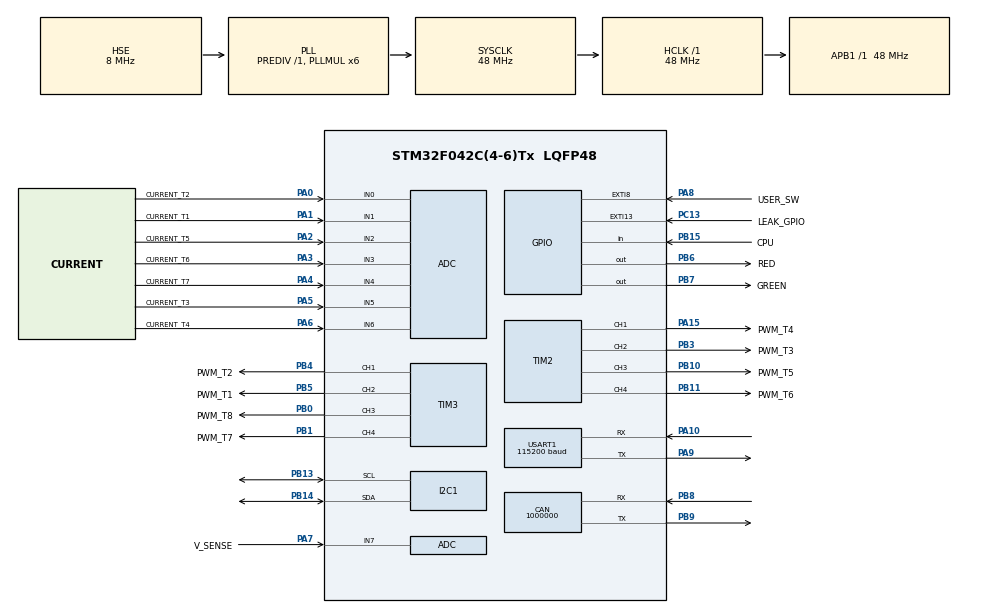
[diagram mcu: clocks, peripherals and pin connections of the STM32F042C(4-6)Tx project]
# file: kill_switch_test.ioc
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CAN.CalculateBaudRate=1000000
CAN.CalculateTimeQuantum=333.3333333333333
Mcu.Family=STM32F0
Mcu.Name=STM32F042C(4-6)Tx
Mcu.Package=LQFP48
PA0.GPIO_Label=CURRENT_T2
PA0.Mode=IN0
PA0.Signal=ADC_IN0
PA1.GPIO_Label=CURRENT_T1
PA1.Mode=IN1
PA1.Signal=ADC_IN1
PA10.Mode=Asynchronous
PA10.Signal=USART1_RX
PA15.GPIO_Label=PWM_T4
PA15.Signal=S_TIM2_CH1_ETR
PA2.GPIO_Label=CURRENT_T5
PA2.Mode=IN2
PA2.Signal=ADC_IN2
PA3.GPIO_Label=CURRENT_T6
PA3.Mode=IN3
PA3.Signal=ADC_IN3
PA4.GPIO_Label=CURRENT_T7
PA4.Mode=IN4
PA4.Signal=ADC_IN4
PA5.GPIO_Label=CURRENT_T3
PA5.Mode=IN5
PA5.Signal=ADC_IN5
PA6.GPIO_Label=CURRENT_T4
PA6.Mode=IN6
PA6.Signal=ADC_IN6
PA7.GPIO_Label=V_SENSE
PA7.Mode=IN7
PA7.Signal=ADC_IN7
PA8.GPIO_Label=USER_SW
PA8.GPIO_ModeDefaultEXTI=GPIO_MODE_EVT_RISING_FALLING
PA8.GPIO_PuPd=GPIO_NOPULL
PA8.Signal=GPXTI8
PA9.Mode=Asynchronous
PA9.Signal=USART1_TX
PB0.GPIO_Label=PWM_T8
PB0.Signal=S_TIM3_CH3
PB1.GPIO_Label=PWM_T7
PB1.Signal=S_TIM3_CH4
PB10.GPIO_Label=PWM_T5
PB10.Signal=S_TIM2_CH3
PB11.GPIO_Label=PWM_T6
PB11.Signal=S_TIM2_CH4
PB13.Mode=I2C
PB13.Signal=I2C1_SCL
PB14.Mode=I2C
PB14.Signal=I2C1_SDA
PB15.GPIO_Label=CPU
PB15.Signal=GPIO_Input
PB3.GPIO_Label=PWM_T3
PB3.Signal=S_TIM2_CH2
PB4.GPIO_Label=PWM_T2
PB4.Signal=S_TIM3_CH1
PB5.GPIO_Label=PWM_T1
PB5.Signal=S_TIM3_CH2
PB6.GPIO_Label=RED
PB6.PinState=GPIO_PIN_SET
PB6.Signal=GPIO_Output
PB7.GPIO_Label=GREEN
PB7.Signal=GPIO_Output
PB8.Mode=CAN_Activate
PB8.Signal=CAN_RX
PB9.Mode=CAN_Activate
PB9.Signal=CAN_TX
PC13.GPIO_Label=LEAK_GPIO
PC13.GPIO_ModeDefaultEXTI=GPIO_MODE_EVT_RISING_FALLING
PC13.Signal=GPXTI13
PF0-OSC_IN.Mode=HSE-External-Oscillator
PF0-OSC_IN.Signal=RCC_OSC_IN
PF1-OSC_OUT.Mode=HSE-External-Oscillator
PF1-OSC_OUT.Signal=RCC_OSC_OUT
ProjectManager.HeapSize=0x200
ProjectManager.StackSize=0x400
ProjectManager.TargetToolchain=STM32CubeIDE
RCC.AHBFreq_Value=48000000
RCC.APB1Freq_Value=48000000
RCC.APB1TimFreq_Value=48000000
RCC.HCLKFreq_Value=48000000
RCC.PLLMUL=RCC_PLL_MUL6
RCC.PLLSourceVirtual=RCC_PLLSOURCE_HSE
RCC.SYSCLKFreq_VALUE=48000000
RCC.SYSCLKSource=RCC_SYSCLKSOURCE_PLLCLK
SH.S_TIM2_CH1_ETR.0=TIM2_CH1,PWM Generation1 CH1
SH.S_TIM2_CH2.0=TIM2_CH2,PWM Generation2 CH2
SH.S_TIM2_CH3.0=TIM2_CH3,PWM Generation3 CH3
SH.S_TIM2_CH4.0=TIM2_CH4,PWM Generation4 CH4
SH.S_TIM3_CH1.0=TIM3_CH1,PWM Generation1 CH1
SH.S_TIM3_CH2.0=TIM3_CH2,PWM Generation2 CH2
SH.S_TIM3_CH3.0=TIM3_CH3,PWM Generation3 CH3
SH.S_TIM3_CH4.0=TIM3_CH4,PWM Generation4 CH4
TIM2.Channel-PWM\ Generation1\ CH1=TIM_CHANNEL_1
TIM2.Channel-PWM\ Generation2\ CH2=TIM_CHANNEL_2
TIM2.Channel-PWM\ Generation3\ CH3=TIM_CHANNEL_3
TIM2.Channel-PWM\ Generation4\ CH4=TIM_CHANNEL_4
TIM3.Channel-PWM\ Generation1\ CH1=TIM_CHANNEL_1
TIM3.Channel-PWM\ Generation2\ CH2=TIM_CHANNEL_2
TIM3.Channel-PWM\ Generation3\ CH3=TIM_CHANNEL_3
TIM3.Channel-PWM\ Generation4\ CH4=TIM_CHANNEL_4
USART1.BaudRate=115200
USART1.VirtualMode-Asynchronous=VM_ASYNC
board=custom

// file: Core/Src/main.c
/* USER CODE BEGIN Header */
/**
  ******************************************************************************
  * @file           : main.c
  * @brief          : Main program body
  ******************************************************************************
  * @attention
  *
  * Copyright (c) 2023 STMicroelectronics.
  * All rights reserved.
  *
  * This software is licensed under terms that can be found in the LICENSE file
  * in the root directory of this software component.
  * If no LICENSE file comes with this software, it is provided AS-IS.
  *
  ******************************************************************************
  */
/* USER CODE END Header */
#include "main.h"

/* USER CODE BEGIN Includes */
#include "printf.h"
#include "string.h"
/* USER CODE END Includes */

ADC_HandleTypeDef hadc;

CAN_HandleTypeDef hcan;

I2C_HandleTypeDef hi2c1;

TIM_HandleTypeDef htim2;
TIM_HandleTypeDef htim3;

UART_HandleTypeDef huart1;

/* USER CODE BEGIN PV */
String KILL_LEAK = "LEAK";
/* USER CODE END PV */

void SystemClock_Config(void);
static void MX_GPIO_Init(void);
static void MX_USART1_UART_Init(void);
static void MX_ADC_Init(void);
static void MX_CAN_Init(void);
static void MX_TIM2_Init(void);
static void MX_TIM3_Init(void);
static void MX_I2C1_Init(void);

int main(void)
{

  /* MCU Configuration--------------------------------------------------------*/

  /* Reset of all peripherals, Initializes the Flash interface and the Systick. */
  HAL_Init();

  /* Configure the system clock */
  SystemClock_Config();

  /* Initialize all configured peripherals */
  MX_GPIO_Init();
  MX_USART1_UART_Init();
  MX_ADC_Init();
  MX_CAN_Init();
  MX_TIM2_Init();
  MX_TIM3_Init();
  MX_I2C1_Init();

  /* Infinite loop */
  /* USER CODE BEGIN WHILE */
  while (1)
  {
	  printf("Hello World!\n");
	  HAL_Delay(200);
	  HAL_GPIO_TogglePin(GREEN_GPIO_Port, GREEN_Pin);
    /* USER CODE END WHILE */

  }
}

void SystemClock_Config(void)
{
  RCC_OscInitTypeDef RCC_OscInitStruct = {0};
  RCC_ClkInitTypeDef RCC_ClkInitStruct = {0};
  RCC_PeriphCLKInitTypeDef PeriphClkInit = {0};

  /** Initializes the RCC Oscillators according to the specified parameters
  * in the RCC_OscInitTypeDef structure.
  */
  RCC_OscInitStruct.OscillatorType = RCC_OSCILLATORTYPE_HSI|RCC_OSCILLATORTYPE_HSI14
                              |RCC_OSCILLATORTYPE_HSE;
  RCC_OscInitStruct.HSEState = RCC_HSE_ON;
  RCC_OscInitStruct.HSIState = RCC_HSI_ON;
  RCC_OscInitStruct.HSI14State = RCC_HSI14_ON;
  RCC_OscInitStruct.HSICalibrationValue = RCC_HSICALIBRATION_DEFAULT;
  RCC_OscInitStruct.HSI14CalibrationValue = 16;
  RCC_OscInitStruct.PLL.PLLState = RCC_PLL_ON;
  RCC_OscInitStruct.PLL.PLLSource = RCC_PLLSOURCE_HSE;
  RCC_OscInitStruct.PLL.PLLMUL = RCC_PLL_MUL6;
  RCC_OscInitStruct.PLL.PREDIV = RCC_PREDIV_DIV1;
  if (HAL_RCC_OscConfig(&RCC_OscInitStruct) != HAL_OK)
  {
    Error_Handler();
  }

  /** Initializes the CPU, AHB and APB buses clocks
  */
  RCC_ClkInitStruct.ClockType = RCC_CLOCKTYPE_HCLK|RCC_CLOCKTYPE_SYSCLK
                              |RCC_CLOCKTYPE_PCLK1;
  RCC_ClkInitStruct.SYSCLKSource = RCC_SYSCLKSOURCE_PLLCLK;
  RCC_ClkInitStruct.AHBCLKDivider = RCC_SYSCLK_DIV1;
  RCC_ClkInitStruct.APB1CLKDivider = RCC_HCLK_DIV1;

  if (HAL_RCC_ClockConfig(&RCC_ClkInitStruct, FLASH_LATENCY_1) != HAL_OK)
  {
    Error_Handler();
  }
  PeriphClkInit.PeriphClockSelection = RCC_PERIPHCLK_USART1|RCC_PERIPHCLK_I2C1;
  PeriphClkInit.Usart1ClockSelection = RCC_USART1CLKSOURCE_PCLK1;
  PeriphClkInit.I2c1ClockSelection = RCC_I2C1CLKSOURCE_HSI;
  if (HAL_RCCEx_PeriphCLKConfig(&PeriphClkInit) != HAL_OK)
  {
    Error_Handler();
  }
}

static void MX_ADC_Init(void)
{

  ADC_ChannelConfTypeDef sConfig = {0};

  /** Configure the global features of the ADC (Clock, Resolution, Data Alignment and number of conversion)
  */
  hadc.Instance = ADC1;
  hadc.Init.ClockPrescaler = ADC_CLOCK_ASYNC_DIV1;
  hadc.Init.Resolution = ADC_RESOLUTION_12B;
  hadc.Init.DataAlign = ADC_DATAALIGN_RIGHT;
  hadc.Init.ScanConvMode = ADC_SCAN_DIRECTION_FORWARD;
  hadc.Init.EOCSelection = ADC_EOC_SINGLE_CONV;
  hadc.Init.LowPowerAutoWait = DISABLE;
  hadc.Init.LowPowerAutoPowerOff = DISABLE;
  hadc.Init.ContinuousConvMode = DISABLE;
  hadc.Init.DiscontinuousConvMode = DISABLE;
  hadc.Init.ExternalTrigConv = ADC_SOFTWARE_START;
  hadc.Init.ExternalTrigConvEdge = ADC_EXTERNALTRIGCONVEDGE_NONE;
  hadc.Init.DMAContinuousRequests = DISABLE;
  hadc.Init.Overrun = ADC_OVR_DATA_PRESERVED;
  if (HAL_ADC_Init(&hadc) != HAL_OK)
  {
    Error_Handler();
  }

  /** Configure for the selected ADC regular channel to be converted.
  */
  sConfig.Channel = ADC_CHANNEL_0;
  sConfig.Rank = ADC_RANK_CHANNEL_NUMBER;
  sConfig.SamplingTime = ADC_SAMPLETIME_1CYCLE_5;
  if (HAL_ADC_ConfigChannel(&hadc, &sConfig) != HAL_OK)
  {
    Error_Handler();
  }

  /** Configure for the selected ADC regular channel to be converted.
  */
  sConfig.Channel = ADC_CHANNEL_1;
  if (HAL_ADC_ConfigChannel(&hadc, &sConfig) != HAL_OK)
  {
    Error_Handler();
  }

  /** Configure for the selected ADC regular channel to be converted.
  */
  sConfig.Channel = ADC_CHANNEL_2;
  if (HAL_ADC_ConfigChannel(&hadc, &sConfig) != HAL_OK)
  {
    Error_Handler();
  }

  /** Configure for the selected ADC regular channel to be converted.
  */
  sConfig.Channel = ADC_CHANNEL_3;
  if (HAL_ADC_ConfigChannel(&hadc, &sConfig) != HAL_OK)
  {
    Error_Handler();
  }

  /** Configure for the selected ADC regular channel to be converted.
  */
  sConfig.Channel = ADC_CHANNEL_4;
  if (HAL_ADC_ConfigChannel(&hadc, &sConfig) != HAL_OK)
  {
    Error_Handler();
  }

  /** Configure for the selected ADC regular channel to be converted.
  */
  sConfig.Channel = ADC_CHANNEL_5;
  if (HAL_ADC_ConfigChannel(&hadc, &sConfig) != HAL_OK)
  {
    Error_Handler();
  }

  /** Configure for the selected ADC regular channel to be converted.
  */
  sConfig.Channel = ADC_CHANNEL_6;
  if (HAL_ADC_ConfigChannel(&hadc, &sConfig) != HAL_OK)
  {
    Error_Handler();
  }

  /** Configure for the selected ADC regular channel to be converted.
  */
  sConfig.Channel = ADC_CHANNEL_7;
  if (HAL_ADC_ConfigChannel(&hadc, &sConfig) != HAL_OK)
  {
    Error_Handler();
  }

}

static void MX_CAN_Init(void)
{

  hcan.Instance = CAN;
  hcan.Init.Prescaler = 16;
  hcan.Init.Mode = CAN_MODE_NORMAL;
  hcan.Init.SyncJumpWidth = CAN_SJW_1TQ;
  hcan.Init.TimeSeg1 = CAN_BS1_1TQ;
  hcan.Init.TimeSeg2 = CAN_BS2_1TQ;
  hcan.Init.TimeTriggeredMode = DISABLE;
  hcan.Init.AutoBusOff = DISABLE;
  hcan.Init.AutoWakeUp = DISABLE;
  hcan.Init.AutoRetransmission = DISABLE;
  hcan.Init.ReceiveFifoLocked = DISABLE;
  hcan.Init.TransmitFifoPriority = DISABLE;
  if (HAL_CAN_Init(&hcan) != HAL_OK)
  {
    Error_Handler();
  }

}

static void MX_I2C1_Init(void)
{

  hi2c1.Instance = I2C1;
  hi2c1.Init.Timing = 0x2000090E;
  hi2c1.Init.OwnAddress1 = 0;
  hi2c1.Init.AddressingMode = I2C_ADDRESSINGMODE_7BIT;
  hi2c1.Init.DualAddressMode = I2C_DUALADDRESS_DISABLE;
  hi2c1.Init.OwnAddress2 = 0;
  hi2c1.Init.OwnAddress2Masks = I2C_OA2_NOMASK;
  hi2c1.Init.GeneralCallMode = I2C_GENERALCALL_DISABLE;
  hi2c1.Init.NoStretchMode = I2C_NOSTRETCH_DISABLE;
  if (HAL_I2C_Init(&hi2c1) != HAL_OK)
  {
    Error_Handler();
  }

  /** Configure Analogue filter
  */
  if (HAL_I2CEx_ConfigAnalogFilter(&hi2c1, I2C_ANALOGFILTER_ENABLE) != HAL_OK)
  {
    Error_Handler();
  }

  /** Configure Digital filter
  */
  if (HAL_I2CEx_ConfigDigitalFilter(&hi2c1, 0) != HAL_OK)
  {
    Error_Handler();
  }

}

static void MX_TIM2_Init(void)
{

  TIM_MasterConfigTypeDef sMasterConfig = {0};
  TIM_OC_InitTypeDef sConfigOC = {0};

  htim2.Instance = TIM2;
  htim2.Init.Prescaler = 0;
  htim2.Init.CounterMode = TIM_COUNTERMODE_UP;
  htim2.Init.Period = 4294967295;
  htim2.Init.ClockDivision = TIM_CLOCKDIVISION_DIV1;
  htim2.Init.AutoReloadPreload = TIM_AUTORELOAD_PRELOAD_DISABLE;
  if (HAL_TIM_PWM_Init(&htim2) != HAL_OK)
  {
    Error_Handler();
  }
  sMasterConfig.MasterOutputTrigger = TIM_TRGO_RESET;
  sMasterConfig.MasterSlaveMode = TIM_MASTERSLAVEMODE_DISABLE;
  if (HAL_TIMEx_MasterConfigSynchronization(&htim2, &sMasterConfig) != HAL_OK)
  {
    Error_Handler();
  }
  sConfigOC.OCMode = TIM_OCMODE_PWM1;
  sConfigOC.Pulse = 0;
  sConfigOC.OCPolarity = TIM_OCPOLARITY_HIGH;
  sConfigOC.OCFastMode = TIM_OCFAST_DISABLE;
  if (HAL_TIM_PWM_ConfigChannel(&htim2, &sConfigOC, TIM_CHANNEL_1) != HAL_OK)
  {
    Error_Handler();
  }
  if (HAL_TIM_PWM_ConfigChannel(&htim2, &sConfigOC, TIM_CHANNEL_2) != HAL_OK)
  {
    Error_Handler();
  }
  if (HAL_TIM_PWM_ConfigChannel(&htim2, &sConfigOC, TIM_CHANNEL_3) != HAL_OK)
  {
    Error_Handler();
  }
  if (HAL_TIM_PWM_ConfigChannel(&htim2, &sConfigOC, TIM_CHANNEL_4) != HAL_OK)
  {
    Error_Handler();
  }
  HAL_TIM_MspPostInit(&htim2);

}

static void MX_TIM3_Init(void)
{

  TIM_MasterConfigTypeDef sMasterConfig = {0};
  TIM_OC_InitTypeDef sConfigOC = {0};

  htim3.Instance = TIM3;
  htim3.Init.Prescaler = 0;
  htim3.Init.CounterMode = TIM_COUNTERMODE_UP;
  htim3.Init.Period = 65535;
  htim3.Init.ClockDivision = TIM_CLOCKDIVISION_DIV1;
  htim3.Init.AutoReloadPreload = TIM_AUTORELOAD_PRELOAD_DISABLE;
  if (HAL_TIM_PWM_Init(&htim3) != HAL_OK)
  {
    Error_Handler();
  }
  sMasterConfig.MasterOutputTrigger = TIM_TRGO_RESET;
  sMasterConfig.MasterSlaveMode = TIM_MASTERSLAVEMODE_DISABLE;
  if (HAL_TIMEx_MasterConfigSynchronization(&htim3, &sMasterConfig) != HAL_OK)
  {
    Error_Handler();
  }
  sConfigOC.OCMode = TIM_OCMODE_PWM1;
  sConfigOC.Pulse = 0;
  sConfigOC.OCPolarity = TIM_OCPOLARITY_HIGH;
  sConfigOC.OCFastMode = TIM_OCFAST_DISABLE;
  if (HAL_TIM_PWM_ConfigChannel(&htim3, &sConfigOC, TIM_CHANNEL_1) != HAL_OK)
  {
    Error_Handler();
  }
  if (HAL_TIM_PWM_ConfigChannel(&htim3, &sConfigOC, TIM_CHANNEL_2) != HAL_OK)
  {
    Error_Handler();
  }
  if (HAL_TIM_PWM_ConfigChannel(&htim3, &sConfigOC, TIM_CHANNEL_3) != HAL_OK)
  {
    Error_Handler();
  }
  if (HAL_TIM_PWM_ConfigChannel(&htim3, &sConfigOC, TIM_CHANNEL_4) != HAL_OK)
  {
    Error_Handler();
  }
  HAL_TIM_MspPostInit(&htim3);

}

static void MX_USART1_UART_Init(void)
{

  huart1.Instance = USART1;
  huart1.Init.BaudRate = 115200;
  huart1.Init.WordLength = UART_WORDLENGTH_8B;
  huart1.Init.StopBits = UART_STOPBITS_1;
  huart1.Init.Parity = UART_PARITY_NONE;
  huart1.Init.Mode = UART_MODE_TX_RX;
  huart1.Init.HwFlowCtl = UART_HWCONTROL_NONE;
  huart1.Init.OverSampling = UART_OVERSAMPLING_16;
  huart1.Init.OneBitSampling = UART_ONE_BIT_SAMPLE_DISABLE;
  huart1.AdvancedInit.AdvFeatureInit = UART_ADVFEATURE_NO_INIT;
  if (HAL_UART_Init(&huart1) != HAL_OK)
  {
    Error_Handler();
  }

}

static void MX_GPIO_Init(void)
{
  GPIO_InitTypeDef GPIO_InitStruct = {0};

  /* GPIO Ports Clock Enable */
  __HAL_RCC_GPIOC_CLK_ENABLE();
  __HAL_RCC_GPIOF_CLK_ENABLE();
  __HAL_RCC_GPIOA_CLK_ENABLE();
  __HAL_RCC_GPIOB_CLK_ENABLE();

  /*Configure GPIO pin Output Level */
  HAL_GPIO_WritePin(RED_GPIO_Port, RED_Pin, GPIO_PIN_SET);

  /*Configure GPIO pin Output Level */
  HAL_GPIO_WritePin(GREEN_GPIO_Port, GREEN_Pin, GPIO_PIN_RESET);

  /*Configure GPIO pin : LEAK_GPIO_Pin */
  GPIO_InitStruct.Pin = LEAK_GPIO_Pin;
  GPIO_InitStruct.Mode = GPIO_MODE_IT_RISING;
  GPIO_InitStruct.Pull = GPIO_NOPULL;
  HAL_GPIO_Init(LEAK_GPIO_GPIO_Port, &GPIO_InitStruct);

  /*Configure GPIO pin : CPU_Pin */
  GPIO_InitStruct.Pin = CPU_Pin;
  GPIO_InitStruct.Mode = GPIO_MODE_INPUT;
  GPIO_InitStruct.Pull = GPIO_NOPULL;
  HAL_GPIO_Init(CPU_GPIO_Port, &GPIO_InitStruct);

  /*Configure GPIO pin : USER_SW_Pin */
  GPIO_InitStruct.Pin = USER_SW_Pin;
  GPIO_InitStruct.Mode = GPIO_MODE_IT_RISING;
  GPIO_InitStruct.Pull = GPIO_NOPULL;
  HAL_GPIO_Init(USER_SW_GPIO_Port, &GPIO_InitStruct);

  /*Configure GPIO pins : RED_Pin GREEN_Pin */
  GPIO_InitStruct.Pin = RED_Pin|GREEN_Pin;
  GPIO_InitStruct.Mode = GPIO_MODE_OUTPUT_PP;
  GPIO_InitStruct.Pull = GPIO_NOPULL;
  GPIO_InitStruct.Speed = GPIO_SPEED_FREQ_LOW;
  HAL_GPIO_Init(GPIOB, &GPIO_InitStruct);

}

/* USER CODE BEGIN 4 */
void HAL_GPIO_EXT_Callback(uint16_t GPIO_Pin)
{
	if (GPIO_Pin == LEAK_GPIO_Pin){
		if (LEAK_GPIO_Pin == 1){
			HAL_GPIO_WritePin(RED_GPIO_Port, RED_Pin, GPIO_PIN_SET);
			HAL_GPIO_WritePin(GREEN_GPIO_Port, GREEN_Pin, GPIO_PIN_RESET);
			printf(KILL_LEAK);
		}

	}
}

void HAL_ADC_ConvCpltCallback (ADC_HandleTypeDef *adc){

	if (adc == &hadc){

	}
}
/* USER CODE END 4 */

void Error_Handler(void)
{
  __disable_irq();
  while (1)
  {
  }
}
